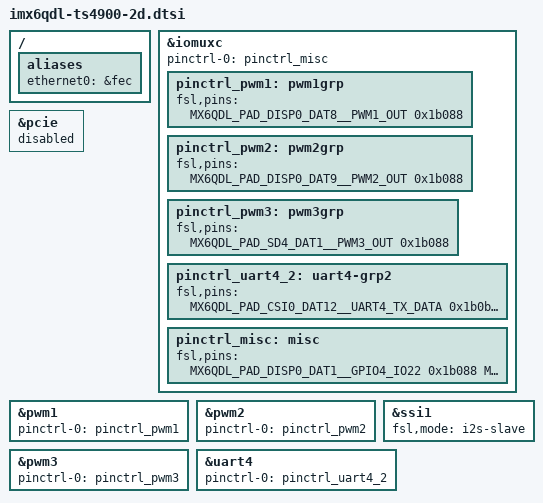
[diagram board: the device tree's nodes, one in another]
/*
 * Copyright 2017-2022 Technologic Systems, Inc. dba embeddedTS
 *
 * This file is dual-licensed: you can use it either under the terms
 * of the GPL or the X11 license, at your option. Note that this dual
 * licensing only applies to this file, and not this project as a
 * whole.
 *
 *  a) This file is free software; you can redistribute it and/or
 *     modify it under the terms of the GNU General Public License
 *     version 2 as published by the Free Software Foundation.
 *
 *     This file is distributed in the hope that it will be useful
 *     but WITHOUT ANY WARRANTY; without even the implied warranty of
 *     MERCHANTABILITY or FITNESS FOR A PARTICULAR PURPOSE.  See the
 *     GNU General Public License for more details.
 *
 * Or, alternatively
 *
 *  b) Permission is hereby granted, free of charge, to any person
 *     obtaining a copy of this software and associated documentation
 *     files (the "Software"), to deal in the Software without
 *     restriction, including without limitation the rights to use
 *     copy, modify, merge, publish, distribute, sublicense, and/or
 *     sell copies of the Software, and to permit persons to whom the
 *     Software is furnished to do so, subject to the following
 *     conditions:
 *
 *     The above copyright notice and this permission notice shall be
 *     included in all copies or substantial portions of the Software.
 *
 *     THE SOFTWARE IS PROVIDED , WITHOUT WARRANTY OF ANY KIND
 *     EXPRESS OR IMPLIED, INCLUDING BUT NOT LIMITED TO THE WARRANTIES
 *     OF MERCHANTABILITY, FITNESS FOR A PARTICULAR PURPOSE AND
 *     NONINFRINGEMENT. IN NO EVENT SHALL THE AUTHORS OR COPYRIGHT
 *     HOLDERS BE LIABLE FOR ANY CLAIM, DAMAGES OR OTHER LIABILITY
 *     WHETHER IN AN ACTION OF CONTRACT, TORT OR OTHERWISE, ARISING
 *     FROM, OUT OF OR IN CONNECTION WITH THE SOFTWARE OR THE USE OR
 *     OTHER DEALINGS IN THE SOFTWARE.
 */

#include <dt-bindings/interrupt-controller/irq.h>

/ {
	aliases {
		ethernet0 = &fec;
	};
};

&iomuxc {
	pinctrl-names = "default";
	pinctrl-0 = <&pinctrl_misc>;

	pinctrl_pwm1: pwm1grp {
		fsl,pins = <
			MX6QDL_PAD_DISP0_DAT8__PWM1_OUT 0x1b088 // PWM_3_3V
		>;
	};

	pinctrl_pwm2: pwm2grp {
		fsl,pins = <
			MX6QDL_PAD_DISP0_DAT9__PWM2_OUT 0x1b088 // PWM_3_3V
		>;
	};

	pinctrl_pwm3: pwm3grp {
		fsl,pins = <
			MX6QDL_PAD_SD4_DAT1__PWM3_OUT 0x1b088
		>;
	};

	pinctrl_uart4_2: uart4-grp2 {
		fsl,pins = <
			MX6QDL_PAD_CSI0_DAT12__UART4_TX_DATA	0x1b0b1
			MX6QDL_PAD_CSI0_DAT13__UART4_RX_DATA	0x1b0b1
		>;
	};

	pinctrl_misc: misc {
		fsl,pins = <
			MX6QDL_PAD_DISP0_DAT1__GPIO4_IO22	0x1b088 // EN_USB_5V
			MX6QDL_PAD_EIM_A17__GPIO2_IO21		0x1b088 // OFF_BD_RESET#
			MX6QDL_PAD_EIM_DA11__GPIO3_IO11		0x1b088 // OUT_1_3V
			MX6QDL_PAD_EIM_DA10__GPIO3_IO10		0x1b088 // OUT_2_3V
			MX6QDL_PAD_EIM_DA9__GPIO3_IO09		0x1b088 // OUT_3_3V
			MX6QDL_PAD_EIM_DA7__GPIO3_IO07		0x1b088 // SEL_422_MODE
			MX6QDL_PAD_EIM_DA5__GPIO3_IO05		0x1b088 // DIG_IN_1
			MX6QDL_PAD_EIM_DA4__GPIO3_IO04		0x1b088 // DIG_IN_2
		>;
	};
};

&pcie {
	status = "disabled";
};

&pwm1 {
	pinctrl-names = "default";
	pinctrl-0 = <&pinctrl_pwm1>;
	status = "okay";
};

&pwm2 {
	pinctrl-names = "default";
	pinctrl-0 = <&pinctrl_pwm2>;
	status = "okay";
};

&pwm3 {
	pinctrl-names = "default";
	pinctrl-0 = <&pinctrl_pwm3>;
	status = "okay";
};

&ssi1 {
	fsl,mode = "i2s-slave";
	status = "okay";
};

&uart4 {
	status = "okay";
	pinctrl-names = "default";
	pinctrl-0 = <&pinctrl_uart4_2>;
};
